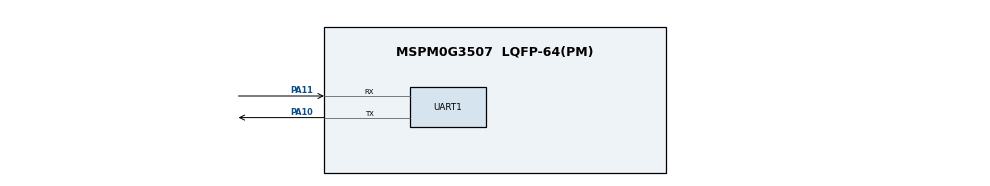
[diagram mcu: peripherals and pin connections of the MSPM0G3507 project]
/**
 * AI AGENTS: Do not edit this file directly. There is no validation or error feedback when
 * editing manually — mistakes will be silent until the file is loaded in SysConfig.
 * Use the SysConfig MCP server instead to make changes with immediate error reporting.
 *
 * These arguments were used when this file was generated. They will be automatically applied on subsequent loads
 * via the GUI or CLI. Run CLI with '--help' for additional information on how to override these arguments.
 * @cliArgs --device "MSPM0G350X" --part "Default" --package "LQFP-64(PM)" --product "mspm0_sdk@2.11.00.07"
 * @v2CliArgs --device "MSPM0G3507" --package "LQFP-64(PM)" --product "mspm0_sdk@2.11.00.07"
 * @versions {"tool":"1.28.0+4696"}
 */

/**
 * Import the modules used in this configuration.
 */
const SYSCTL = scripting.addModule("/ti/driverlib/SYSCTL");
const UART   = scripting.addModule("/ti/driverlib/UART", {}, false);
const UART1  = UART.addInstance();

/**
 * Write custom configuration values to the imported modules.
 */
SYSCTL.forceDefaultClkConfig = true;

const Board = scripting.addModule("/ti/driverlib/Board", {}, false);

UART1.$name                            = "IMU_UART";
UART1.targetBaudRate                   = 115200;
UART1.enabledInterrupts                = ["RX"];
UART1.enableFIFO                       = true;
UART1.rxFifoThreshold                  = "DL_UART_RX_FIFO_LEVEL_ONE_ENTRY";
UART1.peripheral.$assign               = "UART0";
UART1.peripheral.rxPin.$assign         = "PA11";
UART1.peripheral.txPin.$assign         = "PA10";
UART1.txPinConfig.$name                = "ti_driverlib_gpio_GPIOPinGeneric0";
UART1.txPinConfig.direction            = scripting.forceWrite("OUTPUT");
UART1.txPinConfig.hideOutputInversion  = scripting.forceWrite(false);
UART1.txPinConfig.onlyInternalResistor = scripting.forceWrite(false);
UART1.txPinConfig.passedPeripheralType = scripting.forceWrite("Digital");
UART1.rxPinConfig.$name                = "ti_driverlib_gpio_GPIOPinGeneric1";
UART1.rxPinConfig.hideOutputInversion  = scripting.forceWrite(false);
UART1.rxPinConfig.onlyInternalResistor = scripting.forceWrite(false);
UART1.rxPinConfig.passedPeripheralType = scripting.forceWrite("Digital");

/**
 * Pinmux solution for unlocked pins/peripherals. This ensures that minor changes to the automatic solver in a future
 * version of the tool will not impact the pinmux you originally saw.  These lines can be completely deleted in order to
 * re-solve from scratch.
 */
SYSCTL.peripheral.$suggestSolution         = "SYSCTL";
Board.peripheral.$suggestSolution          = "DEBUGSS";
Board.peripheral.swclkPin.$suggestSolution = "PA20";
Board.peripheral.swdioPin.$suggestSolution = "PA19";
